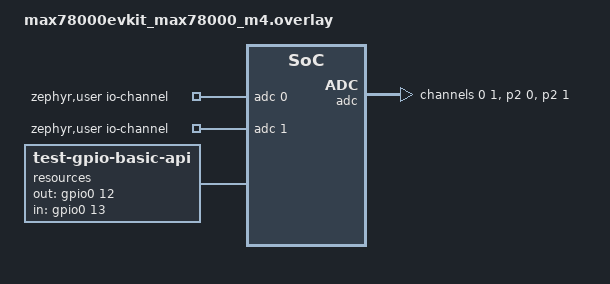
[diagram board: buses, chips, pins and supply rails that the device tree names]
/*
 * Copyright (c) 2025 Analog Devices, Inc.
 *
 * SPDX-License-Identifier: Apache-2.0
 */

tst_dma0: &dma0 {};

/ {
	zephyr,user {
		io-channels = <&adc 0>, <&adc 1>;
	};
};

&adc {
	status = "okay";
	pinctrl-0 = <&ain0_p2_0 &ain1_p2_1>;
	pinctrl-names = "default";
	#address-cells = <1>;
	#size-cells = <0>;
	channel@0 {
		reg = <0>;
		zephyr,gain = "ADC_GAIN_1";
		zephyr,reference = "ADC_REF_INTERNAL";
		zephyr,acquisition-time = <ADC_ACQ_TIME_DEFAULT>;
		zephyr,resolution = <10>;
	};
	channel@1 {
		reg = <1>;
		zephyr,gain = "ADC_GAIN_1";
		zephyr,reference = "ADC_REF_INTERNAL";
		zephyr,acquisition-time = <ADC_ACQ_TIME_DEFAULT>;
		zephyr,resolution = <10>;
	};
};

/ {
	resources {
		compatible = "test-gpio-basic-api";
		out-gpios = <&gpio0 12 0>;
		in-gpios = <&gpio0 13 0>;
	};
};
